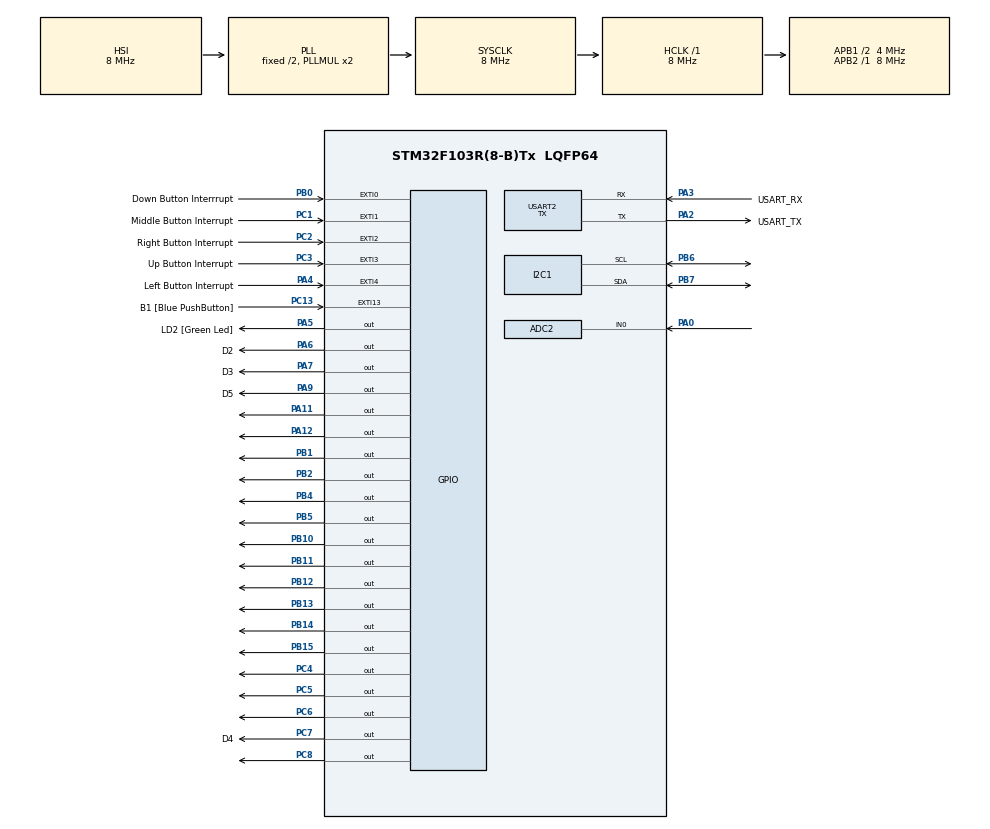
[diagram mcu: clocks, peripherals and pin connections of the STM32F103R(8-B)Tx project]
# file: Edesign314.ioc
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ADC2.Channel-0\#ChannelRegularConversion=ADC_CHANNEL_0
ADC2.NbrOfConversionFlag=1
ADC2.Rank-0\#ChannelRegularConversion=1
ADC2.SamplingTime-0\#ChannelRegularConversion=ADC_SAMPLETIME_1CYCLE_5
Mcu.Family=STM32F1
Mcu.Name=STM32F103R(8-B)Tx
Mcu.Package=LQFP64
NVIC.EXTI0_IRQn=true\:0\:0\:false\:false\:true\:true\:true
NVIC.EXTI15_10_IRQn=true\:0\:0\:false\:false\:true\:true\:true
NVIC.EXTI1_IRQn=true\:0\:0\:false\:false\:true\:true\:true
NVIC.EXTI2_IRQn=true\:0\:0\:false\:false\:true\:true\:true
NVIC.EXTI3_IRQn=true\:0\:0\:false\:false\:true\:true\:true
NVIC.EXTI4_IRQn=true\:0\:0\:false\:false\:true\:true\:true
NVIC.PriorityGroup=NVIC_PRIORITYGROUP_4
PA0-WKUP.Signal=ADCx_IN0
PA11.Signal=GPIO_Output
PA12.Signal=GPIO_Output
PA13.GPIO_Label=TMS
PA13.Mode=Serial_Wire
PA13.Signal=SYS_JTMS-SWDIO
PA14.GPIO_Label=TCK
PA14.Mode=Serial_Wire
PA14.Signal=SYS_JTCK-SWCLK
PA2.GPIO_Label=USART_TX
PA2.GPIO_Mode=GPIO_MODE_AF_PP
PA2.GPIO_PuPd=GPIO_NOPULL
PA2.GPIO_Speed=GPIO_SPEED_FREQ_LOW
PA2.Mode=Asynchronous
PA2.Signal=USART2_TX
PA3.GPIO_Label=USART_RX
PA3.GPIO_Mode=GPIO_MODE_AF_PP
PA3.GPIO_PuPd=GPIO_NOPULL
PA3.GPIO_Speed=GPIO_SPEED_FREQ_LOW
PA3.Mode=Asynchronous
PA3.Signal=USART2_RX
PA4.GPIO_Label=Left Button Interrupt
PA4.GPIO_ModeDefaultEXTI=GPIO_MODE_IT_FALLING
PA4.Signal=GPXTI4
PA5.GPIO_Label=LD2 [Green Led]
PA5.GPIO_ModeDefaultOutputPP=GPIO_MODE_OUTPUT_PP
PA5.GPIO_PuPd=GPIO_NOPULL
PA5.GPIO_Speed=GPIO_SPEED_FREQ_LOW
PA5.Signal=GPIO_Output
PA6.GPIO_Label=D2
PA6.Signal=GPIO_Output
PA7.GPIO_Label=D3
PA7.Signal=GPIO_Output
PA9.GPIO_Label=D5
PA9.Signal=GPIO_Output
PB0.GPIO_Label=Down Button Interrrupt
PB0.GPIO_ModeDefaultEXTI=GPIO_MODE_IT_FALLING
PB0.Signal=GPXTI0
PB1.Signal=GPIO_Output
PB10.Signal=GPIO_Output
PB11.Signal=GPIO_Output
PB12.Signal=GPIO_Output
PB13.Signal=GPIO_Output
PB14.Signal=GPIO_Output
PB15.Signal=GPIO_Output
PB2.Signal=GPIO_Output
PB3.GPIO_Label=SWO
PB3.Signal=SYS_JTDO-TRACESWO
PB4.Signal=GPIO_Output
PB5.Signal=GPIO_Output
PB6.Mode=I2C
PB6.Signal=I2C1_SCL
PB7.Mode=I2C
PB7.Signal=I2C1_SDA
PC1.GPIO_Label=Middle Button Interrupt
PC1.GPIO_ModeDefaultEXTI=GPIO_MODE_IT_FALLING
PC1.Signal=GPXTI1
PC13-TAMPER-RTC.GPIO_Label=B1 [Blue PushButton]
PC13-TAMPER-RTC.GPIO_ModeDefaultEXTI=GPIO_MODE_IT_FALLING
PC13-TAMPER-RTC.GPIO_PuPd=GPIO_NOPULL
PC13-TAMPER-RTC.Signal=GPXTI13
PC14-OSC32_IN.Mode=LSE-External-Oscillator
PC14-OSC32_IN.Signal=RCC_OSC32_IN
PC15-OSC32_OUT.Mode=LSE-External-Oscillator
PC15-OSC32_OUT.Signal=RCC_OSC32_OUT
PC2.GPIO_Label=Right Button Interrupt
PC2.GPIO_ModeDefaultEXTI=GPIO_MODE_IT_FALLING
PC2.Signal=GPXTI2
PC3.GPIO_Label=Up Button Interrupt
PC3.GPIO_ModeDefaultEXTI=GPIO_MODE_IT_FALLING
PC3.Signal=GPXTI3
PC4.Signal=GPIO_Output
PC5.Signal=GPIO_Output
PC6.Signal=GPIO_Output
PC7.GPIO_Label=D4
PC7.Signal=GPIO_Output
PC8.Signal=GPIO_Output
PD0-OSC_IN.Mode=HSE-External-Clock-Source
PD0-OSC_IN.Signal=RCC_OSC_IN
PD1-OSC_OUT.Mode=HSE-External-Clock-Source
PD1-OSC_OUT.Signal=RCC_OSC_OUT
ProjectManager.HeapSize=0x200
ProjectManager.StackSize=0x400
ProjectManager.TargetToolchain=STM32CubeIDE
RCC.AHBFreq_Value=8000000
RCC.APB1CLKDivider=RCC_HCLK_DIV2
RCC.APB1Freq_Value=4000000
RCC.APB1TimFreq_Value=8000000
RCC.APB2Freq_Value=8000000
RCC.APB2TimFreq_Value=8000000
RCC.HCLKFreq_Value=8000000
RCC.RTCClockSelection=RCC_RTCCLKSOURCE_LSE
RCC.SYSCLKFreq_VALUE=8000000
RCC.SYSCLKSource=RCC_SYSCLKSOURCE_PLLCLK
RCC.USBFreq_Value=8000000
SH.ADCx_IN0.0=ADC2_IN0,IN0
USART2.Mode=MODE_TX
USART2.VirtualMode=VM_ASYNC
board=NUCLEO-F103RB

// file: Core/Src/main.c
/* USER CODE BEGIN Header */
/**
  ******************************************************************************
  * @file           : main.c
  * @brief          : Main program body
  ******************************************************************************
  * @attention
  *
  * <h2><center>&copy; Copyright (c) 2021 STMicroelectronics.
  * All rights reserved.</center></h2>
  *
  * This software component is licensed by ST under BSD 3-Clause license,
  * the "License"; You may not use this file except in compliance with the
  * License. You may obtain a copy of the License at:
  *                        opensource.org/licenses/BSD-3-Clause
  *
  ******************************************************************************
  */
/* USER CODE END Header */

#include "main.h"

/* USER CODE BEGIN Includes */
#include "GameCtrl.h"
/* USER CODE END Includes */

ADC_HandleTypeDef hadc2;

I2C_HandleTypeDef hi2c1;

UART_HandleTypeDef huart2;

/* USER CODE BEGIN PV */
extern GPIO_PinState dotmatrix[8][8];
uint8_t i2cdata[6];
/* USER CODE END PV */

void SystemClock_Config(void);
static void MX_GPIO_Init(void);
static void MX_USART2_UART_Init(void);
static void MX_I2C1_Init(void);
static void MX_ADC2_Init(void);

int main(void)
{

  /* MCU Configuration--------------------------------------------------------*/

  /* Reset of all peripherals, Initializes the Flash interface and the Systick. */
  HAL_Init();

  /* Configure the system clock */
  SystemClock_Config();

  /* Initialize all configured peripherals */
  MX_GPIO_Init();
  MX_USART2_UART_Init();
  MX_I2C1_Init();
  MX_ADC2_Init();
  /* USER CODE BEGIN 2 */
	//Setting Up IMU

	HAL_StatusTypeDef res;
	  i2cdata[0]= 0x20;	//ctrl1
	  i2cdata[1]= 0x57; //ODR - 25Hz, X,Y,Z enabled
	  res = HAL_I2C_Master_Transmit(&hi2c1, 0x30, i2cdata, 2, 10);
	  i2cdata[0]= 0x23;	//ctrl1
	  i2cdata[1]= 0x00; //ODR - 25Hz, X,Y,Z enabled
	  HAL_I2C_Master_Transmit(&hi2c1, 0x30, i2cdata, 2, 10);

  gameLoop();
  /* USER CODE END 2 */

  /* Infinite loop */
  while (1)
  {

  }
}

void SystemClock_Config(void)
{
  RCC_OscInitTypeDef RCC_OscInitStruct = {0};
  RCC_ClkInitTypeDef RCC_ClkInitStruct = {0};
  RCC_PeriphCLKInitTypeDef PeriphClkInit = {0};

  /** Initializes the CPU, AHB and APB busses clocks
  */
  RCC_OscInitStruct.OscillatorType = RCC_OSCILLATORTYPE_HSI;
  RCC_OscInitStruct.HSIState = RCC_HSI_ON;
  RCC_OscInitStruct.HSICalibrationValue = RCC_HSICALIBRATION_DEFAULT;
  RCC_OscInitStruct.PLL.PLLState = RCC_PLL_ON;
  RCC_OscInitStruct.PLL.PLLSource = RCC_PLLSOURCE_HSI_DIV2;
  RCC_OscInitStruct.PLL.PLLMUL = RCC_PLL_MUL2;
  if (HAL_RCC_OscConfig(&RCC_OscInitStruct) != HAL_OK)
  {
    Error_Handler();
  }
  /** Initializes the CPU, AHB and APB busses clocks
  */
  RCC_ClkInitStruct.ClockType = RCC_CLOCKTYPE_HCLK|RCC_CLOCKTYPE_SYSCLK
                              |RCC_CLOCKTYPE_PCLK1|RCC_CLOCKTYPE_PCLK2;
  RCC_ClkInitStruct.SYSCLKSource = RCC_SYSCLKSOURCE_PLLCLK;
  RCC_ClkInitStruct.AHBCLKDivider = RCC_SYSCLK_DIV1;
  RCC_ClkInitStruct.APB1CLKDivider = RCC_HCLK_DIV2;
  RCC_ClkInitStruct.APB2CLKDivider = RCC_HCLK_DIV1;

  if (HAL_RCC_ClockConfig(&RCC_ClkInitStruct, FLASH_LATENCY_0) != HAL_OK)
  {
    Error_Handler();
  }
  PeriphClkInit.PeriphClockSelection = RCC_PERIPHCLK_ADC;
  PeriphClkInit.AdcClockSelection = RCC_ADCPCLK2_DIV2;
  if (HAL_RCCEx_PeriphCLKConfig(&PeriphClkInit) != HAL_OK)
  {
    Error_Handler();
  }
}

static void MX_ADC2_Init(void)
{

  ADC_ChannelConfTypeDef sConfig = {0};

  /** Common config
  */
  hadc2.Instance = ADC2;
  hadc2.Init.ScanConvMode = ADC_SCAN_DISABLE;
  hadc2.Init.ContinuousConvMode = DISABLE;
  hadc2.Init.DiscontinuousConvMode = DISABLE;
  hadc2.Init.ExternalTrigConv = ADC_SOFTWARE_START;
  hadc2.Init.DataAlign = ADC_DATAALIGN_RIGHT;
  hadc2.Init.NbrOfConversion = 1;
  if (HAL_ADC_Init(&hadc2) != HAL_OK)
  {
    Error_Handler();
  }
  /** Configure Regular Channel
  */
  sConfig.Channel = ADC_CHANNEL_0;
  sConfig.Rank = ADC_REGULAR_RANK_1;
  sConfig.SamplingTime = ADC_SAMPLETIME_1CYCLE_5;
  if (HAL_ADC_ConfigChannel(&hadc2, &sConfig) != HAL_OK)
  {
    Error_Handler();
  }

}

static void MX_I2C1_Init(void)
{

  hi2c1.Instance = I2C1;
  hi2c1.Init.ClockSpeed = 100000;
  hi2c1.Init.DutyCycle = I2C_DUTYCYCLE_2;
  hi2c1.Init.OwnAddress1 = 0;
  hi2c1.Init.AddressingMode = I2C_ADDRESSINGMODE_7BIT;
  hi2c1.Init.DualAddressMode = I2C_DUALADDRESS_DISABLE;
  hi2c1.Init.OwnAddress2 = 0;
  hi2c1.Init.GeneralCallMode = I2C_GENERALCALL_DISABLE;
  hi2c1.Init.NoStretchMode = I2C_NOSTRETCH_DISABLE;
  if (HAL_I2C_Init(&hi2c1) != HAL_OK)
  {
    Error_Handler();
  }

}

static void MX_USART2_UART_Init(void)
{

  huart2.Instance = USART2;
  huart2.Init.BaudRate = 115200;
  huart2.Init.WordLength = UART_WORDLENGTH_8B;
  huart2.Init.StopBits = UART_STOPBITS_1;
  huart2.Init.Parity = UART_PARITY_NONE;
  huart2.Init.Mode = UART_MODE_TX;
  huart2.Init.HwFlowCtl = UART_HWCONTROL_NONE;
  huart2.Init.OverSampling = UART_OVERSAMPLING_16;
  if (HAL_UART_Init(&huart2) != HAL_OK)
  {
    Error_Handler();
  }

}

static void MX_GPIO_Init(void)
{
  GPIO_InitTypeDef GPIO_InitStruct = {0};

  /* GPIO Ports Clock Enable */
  __HAL_RCC_GPIOC_CLK_ENABLE();
  __HAL_RCC_GPIOD_CLK_ENABLE();
  __HAL_RCC_GPIOA_CLK_ENABLE();
  __HAL_RCC_GPIOB_CLK_ENABLE();

  /*Configure GPIO pin Output Level */
  HAL_GPIO_WritePin(GPIOA, LD2_Pin|D2_Pin|D3_Pin|D5_Pin
                          |GPIO_PIN_11|GPIO_PIN_12, GPIO_PIN_RESET);

  /*Configure GPIO pin Output Level */
  HAL_GPIO_WritePin(GPIOC, GPIO_PIN_4|GPIO_PIN_5|GPIO_PIN_6|D4_Pin
                          |GPIO_PIN_8, GPIO_PIN_RESET);

  /*Configure GPIO pin Output Level */
  HAL_GPIO_WritePin(GPIOB, GPIO_PIN_1|GPIO_PIN_2|GPIO_PIN_10|GPIO_PIN_11
                          |GPIO_PIN_12|GPIO_PIN_13|GPIO_PIN_14|GPIO_PIN_15
                          |GPIO_PIN_4|GPIO_PIN_5, GPIO_PIN_RESET);

  /*Configure GPIO pins : B1_Pin Middle_Button_Interrupt_Pin Right_Button_Interrupt_Pin Up_Button_Interrupt_Pin */
  GPIO_InitStruct.Pin = B1_Pin|Middle_Button_Interrupt_Pin|Right_Button_Interrupt_Pin|Up_Button_Interrupt_Pin;
  GPIO_InitStruct.Mode = GPIO_MODE_IT_FALLING;
  GPIO_InitStruct.Pull = GPIO_NOPULL;
  HAL_GPIO_Init(GPIOC, &GPIO_InitStruct);

  /*Configure GPIO pin : Left_Button_Interrupt_Pin */
  GPIO_InitStruct.Pin = Left_Button_Interrupt_Pin;
  GPIO_InitStruct.Mode = GPIO_MODE_IT_FALLING;
  GPIO_InitStruct.Pull = GPIO_NOPULL;
  HAL_GPIO_Init(Left_Button_Interrupt_GPIO_Port, &GPIO_InitStruct);

  /*Configure GPIO pins : LD2_Pin D2_Pin D3_Pin D5_Pin
                           PA11 PA12 */
  GPIO_InitStruct.Pin = LD2_Pin|D2_Pin|D3_Pin|D5_Pin
                          |GPIO_PIN_11|GPIO_PIN_12;
  GPIO_InitStruct.Mode = GPIO_MODE_OUTPUT_PP;
  GPIO_InitStruct.Pull = GPIO_NOPULL;
  GPIO_InitStruct.Speed = GPIO_SPEED_FREQ_LOW;
  HAL_GPIO_Init(GPIOA, &GPIO_InitStruct);

  /*Configure GPIO pins : PC4 PC5 PC6 D4_Pin
                           PC8 */
  GPIO_InitStruct.Pin = GPIO_PIN_4|GPIO_PIN_5|GPIO_PIN_6|D4_Pin
                          |GPIO_PIN_8;
  GPIO_InitStruct.Mode = GPIO_MODE_OUTPUT_PP;
  GPIO_InitStruct.Pull = GPIO_NOPULL;
  GPIO_InitStruct.Speed = GPIO_SPEED_FREQ_LOW;
  HAL_GPIO_Init(GPIOC, &GPIO_InitStruct);

  /*Configure GPIO pin : Down_Button_Interrrupt_Pin */
  GPIO_InitStruct.Pin = Down_Button_Interrrupt_Pin;
  GPIO_InitStruct.Mode = GPIO_MODE_IT_FALLING;
  GPIO_InitStruct.Pull = GPIO_NOPULL;
  HAL_GPIO_Init(Down_Button_Interrrupt_GPIO_Port, &GPIO_InitStruct);

  /*Configure GPIO pins : PB1 PB2 PB10 PB11
                           PB12 PB13 PB14 PB15
                           PB4 PB5 */
  GPIO_InitStruct.Pin = GPIO_PIN_1|GPIO_PIN_2|GPIO_PIN_10|GPIO_PIN_11
                          |GPIO_PIN_12|GPIO_PIN_13|GPIO_PIN_14|GPIO_PIN_15
                          |GPIO_PIN_4|GPIO_PIN_5;
  GPIO_InitStruct.Mode = GPIO_MODE_OUTPUT_PP;
  GPIO_InitStruct.Pull = GPIO_NOPULL;
  GPIO_InitStruct.Speed = GPIO_SPEED_FREQ_LOW;
  HAL_GPIO_Init(GPIOB, &GPIO_InitStruct);

  /* EXTI interrupt init*/
  HAL_NVIC_SetPriority(EXTI0_IRQn, 0, 0);
  HAL_NVIC_EnableIRQ(EXTI0_IRQn);

  HAL_NVIC_SetPriority(EXTI1_IRQn, 0, 0);
  HAL_NVIC_EnableIRQ(EXTI1_IRQn);

  HAL_NVIC_SetPriority(EXTI2_IRQn, 0, 0);
  HAL_NVIC_EnableIRQ(EXTI2_IRQn);

  HAL_NVIC_SetPriority(EXTI3_IRQn, 0, 0);
  HAL_NVIC_EnableIRQ(EXTI3_IRQn);

  HAL_NVIC_SetPriority(EXTI4_IRQn, 0, 0);
  HAL_NVIC_EnableIRQ(EXTI4_IRQn);

  HAL_NVIC_SetPriority(EXTI15_10_IRQn, 0, 0);
  HAL_NVIC_EnableIRQ(EXTI15_10_IRQn);

}

void Error_Handler(void)
{
}

/************************ (C) COPYRIGHT STMicroelectronics *****END OF FILE****/
